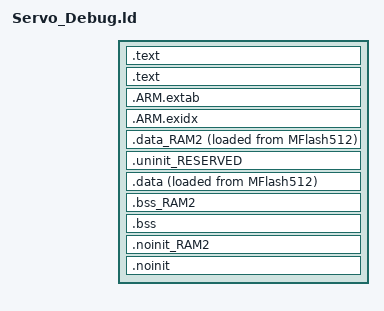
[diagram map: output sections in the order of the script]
/*
 * GENERATED FILE - DO NOT EDIT
 * (c) Code Red Technologies Ltd, 2008-2013
 * (c) NXP Semiconductors 2013-2013
 * Generated linker script file for LPC1769
 * Created from generic_cpp.ld (LPCXpresso v6.1 (0 [Build 164] [2013-10-21] ))
 * By LPCXpresso v6.1.0 [Build 164] [2013-10-21]  on Sun Nov 24 22:06:59 MST 2013
 */


INCLUDE "Servo_Debug_lib.ld"
INCLUDE "Servo_Debug_mem.ld"

ENTRY(ResetISR)

SECTIONS
{

    /* MAIN TEXT SECTION */    
    .text : ALIGN(4)
    {
        FILL(0xff)
        __vectors_start__ = ABSOLUTE(.) ;
        KEEP(*(.isr_vector))
        
        /* Global Section Table */
        . = ALIGN(4) ;
        __section_table_start = .;
        __data_section_table = .;
        LONG(LOADADDR(.data));
        LONG(    ADDR(.data)) ;
        LONG(  SIZEOF(.data));
        LONG(LOADADDR(.data_RAM2));
        LONG(    ADDR(.data_RAM2)) ;
        LONG(  SIZEOF(.data_RAM2));
        __data_section_table_end = .;
        __bss_section_table = .;
        LONG(    ADDR(.bss));
        LONG(  SIZEOF(.bss));
        LONG(    ADDR(.bss_RAM2));
        LONG(  SIZEOF(.bss_RAM2));
        __bss_section_table_end = .;
        __section_table_end = . ;
        /* End of Global Section Table */
        

        *(.after_vectors*)
        
    } >MFlash512
    
    .text : ALIGN(4)    
    {
         *(.text*)
        *(.rodata .rodata.*)
        . = ALIGN(4);
        
        /* C++ constructors etc */
        . = ALIGN(4);
        KEEP(*(.init))
        
        . = ALIGN(4);
        __preinit_array_start = .;
        KEEP (*(.preinit_array))
        __preinit_array_end = .;
        
        . = ALIGN(4);
        __init_array_start = .;
        KEEP (*(SORT(.init_array.*)))
        KEEP (*(.init_array))
        __init_array_end = .;
        
        KEEP(*(.fini));
        
        . = ALIGN(4);
        KEEP (*crtbegin.o(.ctors))
        KEEP (*(EXCLUDE_FILE (*crtend.o) .ctors))
        KEEP (*(SORT(.ctors.*)))
        KEEP (*crtend.o(.ctors))
        
        . = ALIGN(4);
        KEEP (*crtbegin.o(.dtors))
        KEEP (*(EXCLUDE_FILE (*crtend.o) .dtors))
        KEEP (*(SORT(.dtors.*)))
        KEEP (*crtend.o(.dtors))
        /* End C++ */
    } > MFlash512

    /*
     * for exception handling/unwind - some Newlib functions (in common
     * with C++ and STDC++) use this. 
     */
    .ARM.extab : ALIGN(4)
    {
    	*(.ARM.extab* .gnu.linkonce.armextab.*)
    } > MFlash512
    __exidx_start = .;
    
    .ARM.exidx : ALIGN(4)
    {
    	*(.ARM.exidx* .gnu.linkonce.armexidx.*)
    } > MFlash512
    __exidx_end = .;
    
    _etext = .;
        
    
    /* DATA section for RamAHB32 */
    .data_RAM2 : ALIGN(4)
    {
       FILL(0xff)
    	*(.data.$RAM2*)
    	*(.data.$RamAHB32*)
       . = ALIGN(4) ;
    } > RamAHB32 AT>MFlash512
    
    /* MAIN DATA SECTION */
    

    .uninit_RESERVED : ALIGN(4)
    {
        KEEP(*(.bss.$RESERVED*))
        . = ALIGN(4) ;
        _end_uninit_RESERVED = .;
    } > RamLoc32

	
	/* Main DATA section (RamLoc32) */
	.data : ALIGN(4)
	{
	   FILL(0xff)
	   _data = . ;
	   *(vtable)
	   *(.data*)
	   . = ALIGN(4) ;
	   _edata = . ;
	} > RamLoc32 AT>MFlash512

    /* BSS section for RamAHB32 */
    .bss_RAM2 : ALIGN(4)
    {
    	*(.bss.$RAM2*)
    	*(.bss.$RamAHB32*)
       . = ALIGN(4) ;
    } > RamAHB32

    /* MAIN BSS SECTION */
    .bss : ALIGN(4)
    {
        _bss = .;
        *(.bss*)
        *(COMMON)
        . = ALIGN(4) ;
        _ebss = .;
        PROVIDE(end = .);
    } > RamLoc32
        
    /* NOINIT section for RamAHB32 */
    .noinit_RAM2 (NOLOAD) : ALIGN(4)
    {
    	*(.noinit.$RAM2*)
    	*(.noinit.$RamAHB32*)
       . = ALIGN(4) ;
    } > RamAHB32 
    
    /* DEFAULT NOINIT SECTION */
    .noinit (NOLOAD): ALIGN(4)
    {
        _noinit = .;
        *(.noinit*) 
         . = ALIGN(4) ;
        _end_noinit = .;
    } > RamLoc32
    
    PROVIDE(_pvHeapStart = .);
    PROVIDE(_vStackTop = __top_RamLoc32 - 0);
}
